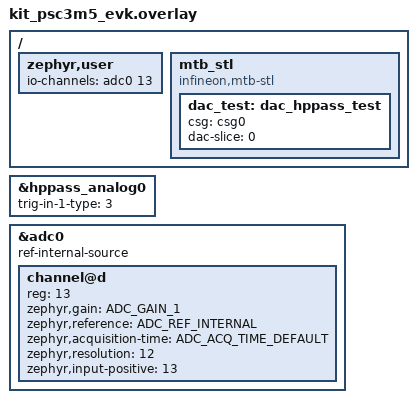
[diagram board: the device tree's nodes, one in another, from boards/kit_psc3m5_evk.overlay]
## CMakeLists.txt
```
# SPDX-License-Identifier: Apache-2.0

cmake_minimum_required(VERSION 3.20.0)

find_package(Zephyr REQUIRED HINTS $ENV{ZEPHYR_BASE})
project(post_dac_stl_sample)

target_sources(app PRIVATE src/main.c)
```

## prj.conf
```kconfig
# POST subsystem
CONFIG_POST=y
CONFIG_POST_VENDOR_MTB_STL=y
CONFIG_POST_SHELL=y
CONFIG_POST_HALT_ON_FAILURE=n
CONFIG_POST_RUNTIME_TESTS=y

# Enable DAC MTB-STL test
CONFIG_POST_MTB_STL_DAC=y

# Zephyr driver configs (HPPASS SAR ADC + CSG DAC)
CONFIG_ADC=y
CONFIG_DAC=y

# Shell support
CONFIG_SHELL=y

# Logging
CONFIG_LOG=y
CONFIG_POST_LOG_LEVEL=4

# Shared interrupts
# Note: This config is enabled by default.
# This config enables to have multiple ISR for same irq line,
# since both test and drivers use same irq line
CONFIG_SHARED_INTERRUPTS=y
```

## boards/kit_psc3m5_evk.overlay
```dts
/*
 * SPDX-FileCopyrightText: Copyright (c) 2026 Infineon Technologies AG,
 * SPDX-FileCopyrightText: or an affiliate of Infineon Technologies AG. All rights reserved.
 *
 * SPDX-License-Identifier: Apache-2.0
 */

#include <zephyr/dt-bindings/adc/adc.h>

&hppass_analog0 {
	trig-in-1-type = <3>;
};

&adc0 {
	status = "okay";
	ref-internal-source;
	#address-cells = <1>;
	#size-cells = <0>;

	channel@d {
		reg = <13>;
		zephyr,gain = "ADC_GAIN_1";
		zephyr,reference = "ADC_REF_INTERNAL";
		zephyr,acquisition-time = <ADC_ACQ_TIME_DEFAULT>;
		zephyr,resolution = <12>;
		zephyr,input-positive = <13>;
	};
};

/ {
	zephyr,user {
		io-channels = <&adc0 13>;
	};

	mtb_stl: mtb_stl {
		compatible = "infineon,mtb-stl";
		status = "okay";

		dac_test: dac_hppass_test {
			csg = <&csg0>;
			dac-slice = <0>;
		};
	};
};
```

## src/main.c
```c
/*
 * Copyright (c) 2026 Aerlync Labs Inc.
 * SPDX-License-Identifier: Apache-2.0
 */

#include <zephyr/kernel.h>
#include <zephyr/post/post.h>
#include <zephyr/shell/shell.h>
#include <zephyr/logging/log.h>

LOG_MODULE_REGISTER(post_dac_sample, LOG_LEVEL_INF);

int main(void)
{
	uint32_t passed;
	uint32_t failed;
	uint32_t skipped;

	printk("\n");
	printk("===========================================\n");
	printk("Starting DAC POST sample application\n");
	printk("===========================================\n");
	printk("\n");

	LOG_INF("POST subsystem initialized");
	LOG_INF("MTB-STL tests registered during boot");

	post_get_summary(&passed, &failed, &skipped);
	printk("POST summary: %u passed, %u failed, %u skipped\n", passed, failed, skipped);

	printk("Available shell commands:\n");
	printk("  post list   - List all registered POST tests\n");
	printk("  post run    - Run runtime POST tests\n");
	printk("  post status - Show POST test results\n");
	printk("\n");

	/* Application main loop */
	while (1) {
		k_sleep(K_SECONDS(5));
		LOG_DBG("Application running...");
	}

	return 0;
}
```
